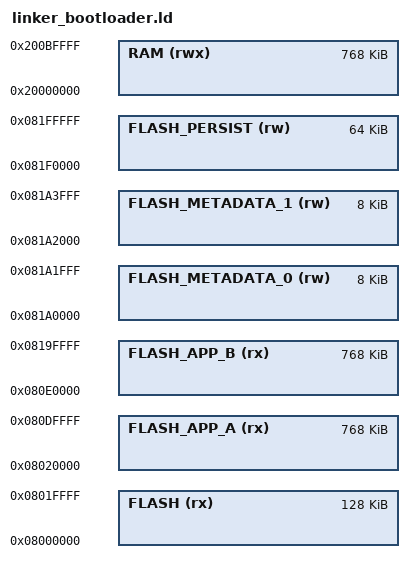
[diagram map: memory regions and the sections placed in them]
/* STM32U7 internal-flash template. Adjust RAM region for the exact package/SRAM banks. */
MEMORY
{
  FLASH (rx) : ORIGIN = 0x08000000, LENGTH = 128K
  FLASH_APP_A (rx) : ORIGIN = 0x08020000, LENGTH = 768K
  FLASH_APP_B (rx) : ORIGIN = 0x080E0000, LENGTH = 768K
  FLASH_METADATA_0 (rw) : ORIGIN = 0x081A0000, LENGTH = 8K
  FLASH_METADATA_1 (rw) : ORIGIN = 0x081A2000, LENGTH = 8K
  FLASH_PERSIST (rw) : ORIGIN = 0x081F0000, LENGTH = 64K
  RAM (rwx)  : ORIGIN = 0x20000000, LENGTH = 768K
}
